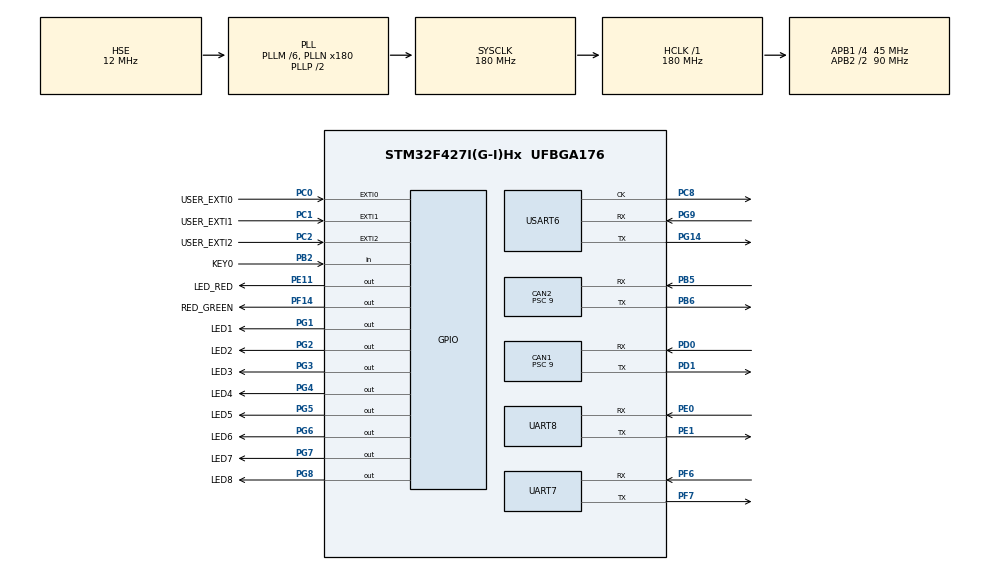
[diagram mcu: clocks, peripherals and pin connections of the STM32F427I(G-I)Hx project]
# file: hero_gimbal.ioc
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CAN1.ABOM=ENABLE
CAN1.BS1=CAN_BS1_2TQ
CAN1.BS2=CAN_BS2_2TQ
CAN1.CalculateBaudRate=1000000
CAN1.CalculateTimeBit=1000
CAN1.CalculateTimeQuantum=200.0
CAN1.Prescaler=9
CAN2.ABOM=ENABLE
CAN2.BS1=CAN_BS1_2TQ
CAN2.BS2=CAN_BS2_2TQ
CAN2.CalculateBaudRate=1000000
CAN2.CalculateTimeBit=1000
CAN2.CalculateTimeQuantum=200.0
CAN2.Prescaler=9
Dma.Request0=UART7_RX
Dma.Request1=UART7_TX
Dma.Request2=UART8_RX
Dma.Request3=UART8_TX
Dma.UART7_RX.0.Direction=DMA_PERIPH_TO_MEMORY
Dma.UART7_RX.0.FIFOMode=DMA_FIFOMODE_DISABLE
Dma.UART7_RX.0.Instance=DMA1_Stream3
Dma.UART7_RX.0.MemDataAlignment=DMA_MDATAALIGN_BYTE
Dma.UART7_RX.0.MemInc=DMA_MINC_ENABLE
Dma.UART7_RX.0.Mode=DMA_NORMAL
Dma.UART7_RX.0.PeriphDataAlignment=DMA_PDATAALIGN_BYTE
Dma.UART7_RX.0.PeriphInc=DMA_PINC_DISABLE
Dma.UART7_RX.0.Priority=DMA_PRIORITY_LOW
Dma.UART7_TX.1.Direction=DMA_MEMORY_TO_PERIPH
Dma.UART7_TX.1.FIFOMode=DMA_FIFOMODE_ENABLE
Dma.UART7_TX.1.FIFOThreshold=DMA_FIFO_THRESHOLD_FULL
Dma.UART7_TX.1.Instance=DMA1_Stream1
Dma.UART7_TX.1.MemBurst=DMA_MBURST_SINGLE
Dma.UART7_TX.1.MemDataAlignment=DMA_MDATAALIGN_BYTE
Dma.UART7_TX.1.MemInc=DMA_MINC_ENABLE
Dma.UART7_TX.1.Mode=DMA_NORMAL
Dma.UART7_TX.1.PeriphBurst=DMA_PBURST_SINGLE
Dma.UART7_TX.1.PeriphDataAlignment=DMA_PDATAALIGN_BYTE
Dma.UART7_TX.1.PeriphInc=DMA_PINC_DISABLE
Dma.UART7_TX.1.Priority=DMA_PRIORITY_LOW
Dma.UART8_RX.2.Direction=DMA_PERIPH_TO_MEMORY
Dma.UART8_RX.2.FIFOMode=DMA_FIFOMODE_DISABLE
Dma.UART8_RX.2.Instance=DMA1_Stream6
Dma.UART8_RX.2.MemDataAlignment=DMA_MDATAALIGN_BYTE
Dma.UART8_RX.2.MemInc=DMA_MINC_ENABLE
Dma.UART8_RX.2.Mode=DMA_NORMAL
Dma.UART8_RX.2.PeriphDataAlignment=DMA_PDATAALIGN_BYTE
Dma.UART8_RX.2.PeriphInc=DMA_PINC_DISABLE
Dma.UART8_RX.2.Priority=DMA_PRIORITY_MEDIUM
Dma.UART8_TX.3.Direction=DMA_MEMORY_TO_PERIPH
Dma.UART8_TX.3.FIFOMode=DMA_FIFOMODE_DISABLE
Dma.UART8_TX.3.Instance=DMA1_Stream0
Dma.UART8_TX.3.MemDataAlignment=DMA_MDATAALIGN_BYTE
Dma.UART8_TX.3.MemInc=DMA_MINC_ENABLE
Dma.UART8_TX.3.Mode=DMA_NORMAL
Dma.UART8_TX.3.PeriphDataAlignment=DMA_PDATAALIGN_BYTE
Dma.UART8_TX.3.PeriphInc=DMA_PINC_DISABLE
Dma.UART8_TX.3.Priority=DMA_PRIORITY_MEDIUM
Mcu.Family=STM32F4
Mcu.Name=STM32F427I(G-I)Hx
Mcu.Package=UFBGA176
Mcu.UserConstants=TIM3_Period,"100ms";TIM4_Quantum,"0_1ms";TIM2_Period,"10ms";TIM4_Period,"1000ms";TIM3_Quantum,"0_1ms";TIM5_Quantum,"0_1ms";TIM5_Period,"1ms";TIM1_Period,"1ms";TIM2_Quantum,"0_1ms";TIM6_Period,"10ms";TIM7_Period,"100ms";TIM8_Period,"1000ms";TIM8_Quantum,"0_1ms";TIM6_Quantum,"0_1ms";TIM7_Quantum,"0_1ms";TIM1_Quantum,"0_01ms";DMA3,UART7_Rx;DMA1,UART7_Tx;DMA6,UART8_Rx;DMA0,UART8_Tx
NVIC.CAN1_RX0_IRQn=true\:7\:0\:true\:false\:true\:true\:true\:true
NVIC.CAN1_SCE_IRQn=true\:2\:0\:true\:false\:true\:true\:true\:true
NVIC.CAN1_TX_IRQn=true\:8\:0\:true\:false\:true\:true\:true\:true
NVIC.CAN2_RX1_IRQn=true\:7\:0\:true\:false\:true\:true\:true\:true
NVIC.CAN2_SCE_IRQn=true\:2\:0\:true\:false\:true\:true\:true\:true
NVIC.CAN2_TX_IRQn=true\:8\:0\:true\:false\:true\:true\:true\:true
NVIC.DMA1_Stream0_IRQn=true\:15\:0\:true\:false\:true\:false\:true\:true
NVIC.DMA1_Stream1_IRQn=true\:15\:0\:true\:false\:true\:false\:true\:true
NVIC.DMA1_Stream3_IRQn=true\:15\:0\:true\:false\:true\:false\:true\:true
NVIC.DMA1_Stream6_IRQn=true\:3\:0\:true\:false\:true\:false\:true\:true
NVIC.EXTI0_IRQn=true\:15\:0\:true\:false\:true\:true\:true\:true
NVIC.EXTI1_IRQn=true\:15\:0\:true\:false\:true\:true\:true\:true
NVIC.EXTI2_IRQn=true\:15\:0\:true\:false\:true\:true\:true\:true
NVIC.PriorityGroup=NVIC_PRIORITYGROUP_4
NVIC.RTC_Alarm_IRQn=true\:4\:0\:true\:false\:true\:true\:true\:true
NVIC.TIM1_UP_TIM10_IRQn=true\:4\:0\:true\:false\:true\:true\:true\:true
NVIC.TIM2_IRQn=true\:4\:0\:true\:false\:true\:true\:true\:true
NVIC.TIM3_IRQn=true\:4\:0\:true\:false\:true\:true\:true\:true
NVIC.TIM4_IRQn=true\:9\:0\:true\:false\:true\:true\:true\:true
NVIC.TIM5_IRQn=true\:15\:0\:true\:false\:true\:true\:true\:true
NVIC.TIM6_DAC_IRQn=true\:15\:0\:true\:false\:true\:true\:true\:true
NVIC.TIM7_IRQn=true\:15\:0\:true\:false\:true\:true\:true\:true
NVIC.TIM8_TRG_COM_TIM14_IRQn=true\:9\:0\:true\:false\:true\:true\:true\:true
NVIC.TIM8_UP_TIM13_IRQn=true\:9\:0\:true\:false\:true\:true\:true\:true
NVIC.UART7_IRQn=true\:7\:0\:true\:false\:true\:true\:true\:true
NVIC.UART8_IRQn=true\:7\:0\:true\:false\:true\:true\:true\:true
NVIC.USART6_IRQn=true\:7\:0\:true\:false\:true\:true\:true\:true
PA13.Mode=Serial_Wire
PA13.Signal=SYS_JTMS-SWDIO
PA14.Mode=Serial_Wire
PA14.Signal=SYS_JTCK-SWCLK
PB2/BOOT1.GPIO_Label=KEY0
PB2/BOOT1.GPIO_PuPd=GPIO_PULLDOWN
PB2/BOOT1.Signal=GPIO_Input
PB5.Mode=CAN_Activate
PB5.Signal=CAN2_RX
PB6.Mode=CAN_Activate
PB6.Signal=CAN2_TX
PC0.GPIO_Label=USER_EXTI0
PC0.GPIO_ModeDefaultEXTI=GPIO_MODE_IT_RISING
PC0.GPIO_PuPd=GPIO_PULLDOWN
PC0.Signal=GPXTI0
PC1.GPIO_Label=USER_EXTI1
PC1.GPIO_PuPd=GPIO_PULLDOWN
PC1.Signal=GPXTI1
PC14/OSC32_IN.Mode=LSE-External-Oscillator
PC14/OSC32_IN.Signal=RCC_OSC32_IN
PC15/OSC32_OUT.Mode=LSE-External-Oscillator
PC15/OSC32_OUT.Signal=RCC_OSC32_OUT
PC2.GPIO_Label=USER_EXTI2
PC2.GPIO_ModeDefaultEXTI=GPIO_MODE_IT_FALLING
PC2.GPIO_PuPd=GPIO_PULLUP
PC2.Signal=GPXTI2
PC8.Mode=Synchronous
PC8.Signal=USART6_CK
PD0.Mode=CAN_Activate
PD0.Signal=CAN1_RX
PD1.Mode=CAN_Activate
PD1.Signal=CAN1_TX
PE0.Mode=Asynchronous
PE0.Signal=UART8_RX
PE1.Mode=Asynchronous
PE1.Signal=UART8_TX
PE11.GPIO_Label=LED_RED
PE11.GPIO_PuPd=GPIO_PULLUP
PE11.PinState=GPIO_PIN_SET
PE11.Signal=GPIO_Output
PF14.GPIO_Label=RED_GREEN
PF14.GPIO_PuPd=GPIO_PULLUP
PF14.PinState=GPIO_PIN_SET
PF14.Signal=GPIO_Output
PF6.Mode=Asynchronous
PF6.Signal=UART7_RX
PF7.Mode=Asynchronous
PF7.Signal=UART7_TX
PG1.GPIO_Label=LED1
PG1.GPIO_PuPd=GPIO_PULLUP
PG1.PinState=GPIO_PIN_SET
PG1.Signal=GPIO_Output
PG14.Mode=Synchronous
PG14.Signal=USART6_TX
PG2.GPIO_Label=LED2
PG2.GPIO_PuPd=GPIO_PULLUP
PG2.PinState=GPIO_PIN_SET
PG2.Signal=GPIO_Output
PG3.GPIO_Label=LED3
PG3.GPIO_PuPd=GPIO_PULLUP
PG3.PinState=GPIO_PIN_SET
PG3.Signal=GPIO_Output
PG4.GPIO_Label=LED4
PG4.GPIO_ModeDefaultOutputPP=GPIO_MODE_OUTPUT_PP
PG4.GPIO_PuPd=GPIO_PULLUP
PG4.PinState=GPIO_PIN_SET
PG4.Signal=GPIO_Output
PG5.GPIO_Label=LED5
PG5.GPIO_PuPd=GPIO_PULLUP
PG5.PinState=GPIO_PIN_SET
PG5.Signal=GPIO_Output
PG6.GPIO_Label=LED6
PG6.GPIO_PuPd=GPIO_PULLUP
PG6.PinState=GPIO_PIN_SET
PG6.Signal=GPIO_Output
PG7.GPIO_Label=LED7
PG7.GPIO_PuPd=GPIO_PULLUP
PG7.PinState=GPIO_PIN_SET
PG7.Signal=GPIO_Output
PG8.GPIO_Label=LED8
PG8.GPIO_PuPd=GPIO_PULLUP
PG8.PinState=GPIO_PIN_SET
PG8.Signal=GPIO_Output
PG9.Mode=Synchronous
PG9.Signal=USART6_RX
PH0/OSC_IN.Mode=HSE-External-Oscillator
PH0/OSC_IN.Signal=RCC_OSC_IN
PH1/OSC_OUT.Mode=HSE-External-Oscillator
PH1/OSC_OUT.Signal=RCC_OSC_OUT
ProjectManager.HeapSize=0x200
ProjectManager.StackSize=0x400
ProjectManager.TargetToolchain=Makefile
RCC.48MHZClocksFreq_Value=90000000
RCC.AHBFreq_Value=180000000
RCC.APB1CLKDivider=RCC_HCLK_DIV4
RCC.APB1Freq_Value=45000000
RCC.APB1TimFreq_Value=90000000
RCC.APB2CLKDivider=RCC_HCLK_DIV2
RCC.APB2Freq_Value=90000000
RCC.APB2TimFreq_Value=180000000
RCC.CortexFreq_Value=180000000
RCC.EnbaleCSS=true
RCC.HCLKFreq_Value=180000000
RCC.HSE_VALUE=12000000
RCC.HSI_VALUE=16000000
RCC.PLLM=6
RCC.PLLN=180
RCC.PLLSourceVirtual=RCC_PLLSOURCE_HSE
RCC.RCC_RTC_Clock_Source=RCC_RTCCLKSOURCE_LSI
RCC.RCC_RTC_Clock_SourceVirtual=RCC_RTCCLKSOURCE_LSE
RCC.SYSCLKFreq_VALUE=180000000
RCC.SYSCLKSource=RCC_SYSCLKSOURCE_PLLCLK
RCC.VCOOutputFreq_Value=360000000
RTC.Alarm=RTC_ALARM_A
RTC.Alarm_B=RTC_ALARM_B
RTC.Date=14
RTC.Month=RTC_MONTH_DECEMBER
RTC.WeekDay=RTC_WEEKDAY_THURSDAY
RTC.Year=23
TIM1.AutoReloadPreload=TIM_AUTORELOAD_PRELOAD_ENABLE
TIM1.Period=100
TIM1.Prescaler=1799
TIM1.TIM_MasterOutputTrigger=TIM_TRGO_UPDATE
TIM2.AutoReloadPreload=TIM_AUTORELOAD_PRELOAD_ENABLE
TIM2.Period=100
TIM2.Prescaler=8999
TIM2.TIM_MasterOutputTrigger=TIM_TRGO_UPDATE
TIM3.AutoReloadPreload=TIM_AUTORELOAD_PRELOAD_ENABLE
TIM3.Period=1000
TIM3.Prescaler=8999
TIM3.TIM_MasterOutputTrigger=TIM_TRGO_UPDATE
TIM4.AutoReloadPreload=TIM_AUTORELOAD_PRELOAD_ENABLE
TIM4.Period=10000
TIM4.Prescaler=8999
TIM4.TIM_MasterOutputTrigger=TIM_TRGO_ENABLE
TIM5.AutoReloadPreload=TIM_AUTORELOAD_PRELOAD_ENABLE
TIM5.Period=10
TIM5.Prescaler=8999
TIM5.TIM_MasterOutputTrigger=TIM_TRGO_UPDATE
TIM6.AutoReloadPreload=TIM_AUTORELOAD_PRELOAD_ENABLE
TIM6.Period=100
TIM6.Prescaler=8999
TIM6.TIM_MasterOutputTrigger=TIM_TRGO_UPDATE
TIM7.AutoReloadPreload=TIM_AUTORELOAD_PRELOAD_ENABLE
TIM7.Period=1000
TIM7.Prescaler=8999
TIM7.TIM_MasterOutputTrigger=TIM_TRGO_UPDATE
TIM8.AutoReloadPreload=TIM_AUTORELOAD_PRELOAD_ENABLE
TIM8.ClockDivision=TIM_CLOCKDIVISION_DIV1
TIM8.Period=10000
TIM8.Prescaler=17999
UART7.VirtualMode=Asynchronous
UART8.VirtualMode=Asynchronous
USART6.Parity=PARITY_EVEN
USART6.VirtualMode=VM_SYNC
VP_CRC_VS_CRC.Mode=CRC_Activate
VP_RTC_VS_RTC_Activate.Mode=RTC_Enabled
VP_RTC_VS_RTC_Alarm_A_Intern.Mode=Alarm A
VP_RTC_VS_RTC_Alarm_B_Intern.Mode=Alarm B
VP_RTC_VS_RTC_Calendar.Mode=RTC_Calendar
VP_TIM1_VS_ClockSourceINT.Mode=Internal
VP_TIM2_VS_ClockSourceINT.Mode=Internal
VP_TIM3_VS_ClockSourceINT.Mode=Internal
VP_TIM4_VS_ClockSourceINT.Mode=Internal
VP_TIM5_VS_ClockSourceINT.Mode=Internal
VP_TIM6_VS_ClockSourceINT.Mode=Enable_Timer
VP_TIM7_VS_ClockSourceINT.Mode=Enable_Timer
VP_TIM8_VS_ClockSourceINT.Mode=Internal
VP_TIM8_VS_ClockSourceITR.Mode=TriggerSource_ITR2
VP_TIM8_VS_ControllerModeGated.Mode=Gated Mode
board=custom

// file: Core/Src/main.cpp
/* USER CODE BEGIN Header */
/**
  ******************************************************************************
  * @file           : main.c
  * @brief          : Main program body
  ******************************************************************************
  * @attention
  *
  * Copyright (c) 2023 STMicroelectronics.
  * All rights reserved.
  *
  * This software is licensed under terms that can be found in the LICENSE file
  * in the root directory of this software component.
  * If no LICENSE file comes with this software, it is provided AS-IS.
  *
  ******************************************************************************
  */
/* USER CODE END Header */
#include "main.h"
#include "can.h"
#include "crc.h"
#include "dma.h"
#include "rtc.h"
#include "tim.h"
#include "usart.h"
#include "gpio.h"

//BSP

#include "bsp_tim.h"
#include "bsp_usart.h"
#include "bsp_led.h"
#include "bsp_can.h"

//MODULES
//APP
#include "msg_center.h"
#include "gimbal_task.h"
#include "cv_communication.h"

/* USER CODE BEGIN PV */
uint8_t tmpu8[10] = {0,0,0,0,0,0,0,0,0,0};

uint16_t tmpu16[10] = {0,0,0,0,0,0,0,0,0,0};
uint32_t tmpu32[10] = {0,0,0,0,0,0,0,0,0,0};
float tmpfloat[10] = {0,0,0,0,0,0,0,0,0,0};
SEND_STATE tmpst[4] = {SEND_SUCCESS,SEND_SUCCESS,SEND_SUCCESS,SEND_SUCCESS};
CV_DATA* tmpcv = &Global_cv_node.plocal_data;
GIMBAL_DATA* tmpgim = &Global_gimbal_node.plocal_data;

/* USER CODE END PV */

void SystemClock_Config(void);

int main(void)
{

  /* MCU Configuration--------------------------------------------------------*/

  /* Reset of all peripherals, Initializes the Flash interface and the Systick. */
  HAL_Init();

  /* Configure the system clock */
  SystemClock_Config();

  /* Initialize all configured peripherals */
  MX_GPIO_Init();
  MX_DMA_Init();
  MX_CAN1_Init();
  MX_CAN2_Init();
  MX_RTC_Init();
  MX_TIM2_Init();
  MX_UART8_Init();
  MX_UART7_Init();
  MX_USART6_Init();
  MX_CRC_Init();
  MX_TIM1_Init();
  MX_TIM3_Init();
  MX_TIM5_Init();
  MX_TIM6_Init();
  MX_TIM7_Init();
  MX_TIM4_Init();
  MX_TIM8_Init();

  Global_tim1.add_task(msg_center_run);
  Global_tim2.add_task(msg_center_update_second);
  Global_tim2.add_task(gimbal_update_second);
  Global_tim3.add_task(cv_run);
  Global_tim5.add_task(gimbal_run);

  Global_usart8.set_rx_callback(led2_blink);

  Global_can1.set_tx_callback(led3_blink);
  Global_can1.add_rx_callback(led4_blink);
  Global_can1.add_rx_callback(yaw_control);

  Global_can2.set_tx_callback(led5_blink);
  Global_can2.add_rx_callback(led7_blink);
  Global_can2.add_rx_callback(pitch_control);

  Global_usart8.start();
  Global_can1.start();
  Global_can2.start();

  Global_tim1.start_task();
  HAL_Delay(2);
  Global_tim2.start_task();
  HAL_Delay(2);
  Global_tim3.start_task();
  HAL_Delay(2);
  Global_tim5.start_task();
  HAL_Delay(2);

  *tmpcv = *tmpcv;
  *tmpgim = *tmpgim;
  /* Infinite loop */
  while (1)
  {

    HAL_GPIO_TogglePin(LED_GREEN_GPIO_Port,LED_GREEN_Pin);
    HAL_Delay(1000);

  }
}

void SystemClock_Config(void)
{
  RCC_OscInitTypeDef RCC_OscInitStruct = {0};
  RCC_ClkInitTypeDef RCC_ClkInitStruct = {0};

  /** Configure the main internal regulator output voltage
  */
  __HAL_RCC_PWR_CLK_ENABLE();
  __HAL_PWR_VOLTAGESCALING_CONFIG(PWR_REGULATOR_VOLTAGE_SCALE1);

  /** Initializes the RCC Oscillators according to the specified parameters
  * in the RCC_OscInitTypeDef structure.
  */
  RCC_OscInitStruct.OscillatorType = RCC_OSCILLATORTYPE_LSI|RCC_OSCILLATORTYPE_HSE;
  RCC_OscInitStruct.HSEState = RCC_HSE_ON;
  RCC_OscInitStruct.LSIState = RCC_LSI_ON;
  RCC_OscInitStruct.PLL.PLLState = RCC_PLL_ON;
  RCC_OscInitStruct.PLL.PLLSource = RCC_PLLSOURCE_HSE;
  RCC_OscInitStruct.PLL.PLLM = 6;
  RCC_OscInitStruct.PLL.PLLN = 180;
  RCC_OscInitStruct.PLL.PLLP = RCC_PLLP_DIV2;
  RCC_OscInitStruct.PLL.PLLQ = 4;
  if (HAL_RCC_OscConfig(&RCC_OscInitStruct) != HAL_OK)
  {
    Error_Handler();
  }

  /** Activate the Over-Drive mode
  */
  if (HAL_PWREx_EnableOverDrive() != HAL_OK)
  {
    Error_Handler();
  }

  /** Initializes the CPU, AHB and APB buses clocks
  */
  RCC_ClkInitStruct.ClockType = RCC_CLOCKTYPE_HCLK|RCC_CLOCKTYPE_SYSCLK
                              |RCC_CLOCKTYPE_PCLK1|RCC_CLOCKTYPE_PCLK2;
  RCC_ClkInitStruct.SYSCLKSource = RCC_SYSCLKSOURCE_PLLCLK;
  RCC_ClkInitStruct.AHBCLKDivider = RCC_SYSCLK_DIV1;
  RCC_ClkInitStruct.APB1CLKDivider = RCC_HCLK_DIV4;
  RCC_ClkInitStruct.APB2CLKDivider = RCC_HCLK_DIV2;

  if (HAL_RCC_ClockConfig(&RCC_ClkInitStruct, FLASH_LATENCY_5) != HAL_OK)
  {
    Error_Handler();
  }

  /** Enables the Clock Security System
  */
  //HAL_RCC_EnableCSS();
}

void Error_Handler(void)
{
  __disable_irq();
  while (1)
  {
  }
}
